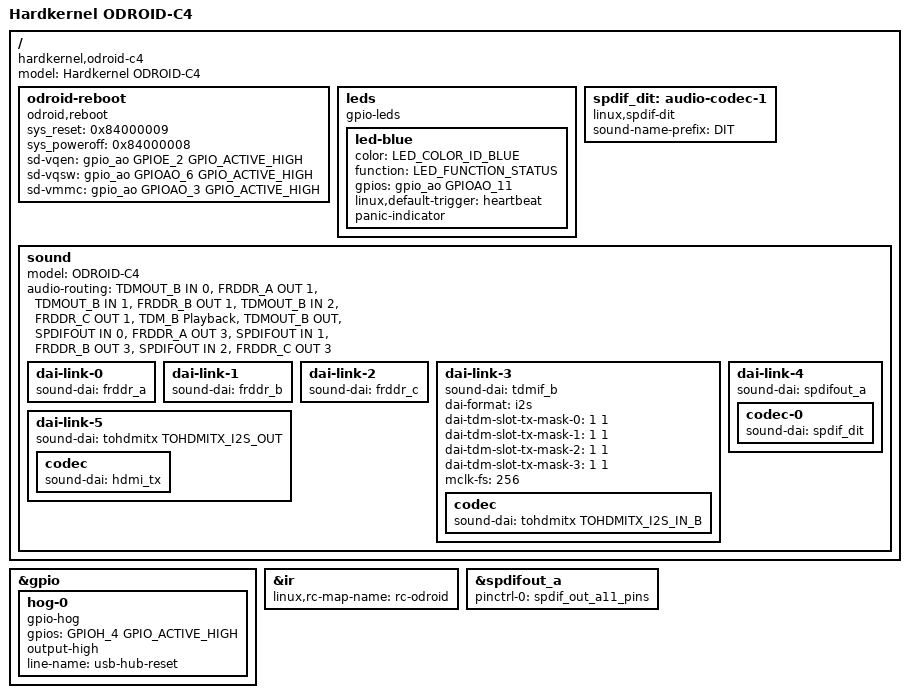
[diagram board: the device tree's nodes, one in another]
// SPDX-License-Identifier: (GPL-2.0+ OR MIT)
/*
 * Copyright (c) 2020 Dongjin Kim <tobetter@gmail.com>
 */

/dts-v1/;

#include "meson-sm1-odroid.dtsi"

/ {
	compatible = "hardkernel,odroid-c4", "amlogic,sm1";
	model = "Hardkernel ODROID-C4";
	status = "okay";

	odroid-reboot {
		compatible = "odroid,reboot";
		sys_reset = <0x84000009>;
		sys_poweroff = <0x84000008>;

		sd-vqen = <&gpio_ao GPIOE_2 GPIO_ACTIVE_HIGH>;
		sd-vqsw = <&gpio_ao GPIOAO_6 GPIO_ACTIVE_HIGH>;
		sd-vmmc = <&gpio_ao GPIOAO_3 GPIO_ACTIVE_HIGH>;
	};

	leds {
		compatible = "gpio-leds";

		led-blue {
			color = <LED_COLOR_ID_BLUE>;
			function = LED_FUNCTION_STATUS;
			gpios = <&gpio_ao GPIOAO_11 GPIO_ACTIVE_HIGH>;
			linux,default-trigger = "heartbeat";
			panic-indicator;
		};
	};

	spdif_dit: audio-codec-1 {
		#sound-dai-cells = <0>;
		compatible = "linux,spdif-dit";
		status = "okay";
		sound-name-prefix = "DIT";
	};

	sound {
		model = "ODROID-C4";
		audio-routing = "TDMOUT_B IN 0", "FRDDR_A OUT 1",
 				"TDMOUT_B IN 1", "FRDDR_B OUT 1",
 				"TDMOUT_B IN 2", "FRDDR_C OUT 1",	
				"TDM_B Playback", "TDMOUT_B OUT",
				"SPDIFOUT IN 0", "FRDDR_A OUT 3",
				"SPDIFOUT IN 1", "FRDDR_B OUT 3",
				"SPDIFOUT IN 2", "FRDDR_C OUT 3";

		dai-link-0 {
			sound-dai = <&frddr_a>;
		};

		dai-link-1 {
			sound-dai = <&frddr_b>;
		};

		dai-link-2 {
			sound-dai = <&frddr_c>;
		};

		/* 8ch hdmi interface */
		dai-link-3 {
			sound-dai = <&tdmif_b>;
			dai-format = "i2s";
			dai-tdm-slot-tx-mask-0 = <1 1>;
			dai-tdm-slot-tx-mask-1 = <1 1>;
			dai-tdm-slot-tx-mask-2 = <1 1>;
			dai-tdm-slot-tx-mask-3 = <1 1>;
			mclk-fs = <256>;

			codec {
				sound-dai = <&tohdmitx TOHDMITX_I2S_IN_B>;
			};
		};				
		/* spdif */
 		dai-link-4 {
			sound-dai = <&spdifout_a>;

			codec-0 {
				sound-dai = <&spdif_dit>;
			};
		};

		/* hdmi glue */
		dai-link-5 {
 			sound-dai = <&tohdmitx TOHDMITX_I2S_OUT>;
 
 			codec {
 				sound-dai = <&hdmi_tx>;
 			};	
		};		
	};
};

&gpio {
	/*
	 * WARNING: The USB Hub on the Odroid-C4 needs a reset signal
	 * to be turned high in order to be detected by the USB Controller
	 * This signal should be handled by a USB specific power sequence
	 * in order to reset the Hub when USB bus is powered down.
	 */
	hog-0 {
		gpio-hog;
		gpios = <GPIOH_4 GPIO_ACTIVE_HIGH>;
		output-high;
		line-name = "usb-hub-reset";
	};
};

&ir {
	linux,rc-map-name = "rc-odroid";
};

&spdifout_a {
	pinctrl-0 = <&spdif_out_a11_pins>;
	pinctrl-names = "default";
	status = "okay";
};
